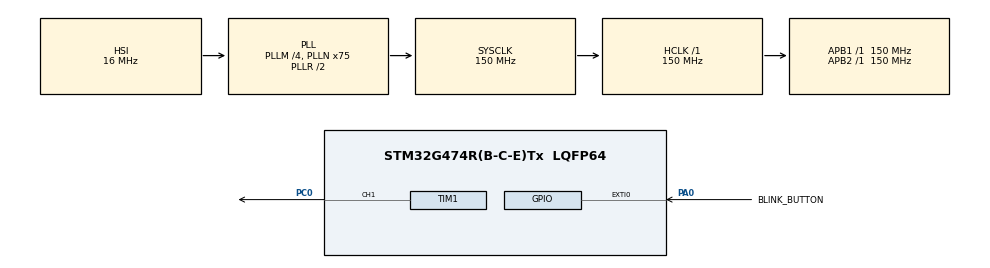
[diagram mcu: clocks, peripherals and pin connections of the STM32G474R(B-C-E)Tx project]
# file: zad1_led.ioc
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Dma.Request0=TIM1_CH1
Dma.TIM1_CH1.0.Direction=DMA_MEMORY_TO_PERIPH
Dma.TIM1_CH1.0.EventEnable=DISABLE
Dma.TIM1_CH1.0.Instance=DMA1_Channel1
Dma.TIM1_CH1.0.MemDataAlignment=DMA_MDATAALIGN_BYTE
Dma.TIM1_CH1.0.MemInc=DMA_MINC_ENABLE
Dma.TIM1_CH1.0.Mode=DMA_NORMAL
Dma.TIM1_CH1.0.PeriphDataAlignment=DMA_PDATAALIGN_HALFWORD
Dma.TIM1_CH1.0.PeriphInc=DMA_PINC_DISABLE
Dma.TIM1_CH1.0.Polarity=HAL_DMAMUX_REQ_GEN_RISING
Dma.TIM1_CH1.0.Priority=DMA_PRIORITY_LOW
Dma.TIM1_CH1.0.RequestNumber=1
Dma.TIM1_CH1.0.SignalID=NONE
Dma.TIM1_CH1.0.SyncEnable=DISABLE
Dma.TIM1_CH1.0.SyncPolarity=HAL_DMAMUX_SYNC_NO_EVENT
Dma.TIM1_CH1.0.SyncRequestNumber=1
Dma.TIM1_CH1.0.SyncSignalID=NONE
Mcu.Family=STM32G4
Mcu.Name=STM32G474R(B-C-E)Tx
Mcu.Package=LQFP64
NVIC.DMA1_Channel1_IRQn=true\:0\:0\:false\:false\:true\:false\:true\:true
NVIC.EXTI0_IRQn=true\:0\:0\:false\:false\:true\:true\:true\:true
NVIC.PriorityGroup=NVIC_PRIORITYGROUP_4
PA0.GPIO_Label=BLINK_BUTTON
PA0.GPIO_ModeDefaultEXTI=GPIO_MODE_IT_FALLING
PA0.Signal=GPXTI0
PC0.Signal=S_TIM1_CH1
ProjectManager.HeapSize=0x200
ProjectManager.StackSize=0x400
ProjectManager.TargetToolchain=STM32CubeIDE
RCC.ADC12Freq_Value=150000000
RCC.ADC345Freq_Value=150000000
RCC.AHBFreq_Value=150000000
RCC.APB1Freq_Value=150000000
RCC.APB1TimFreq_Value=150000000
RCC.APB2Freq_Value=150000000
RCC.APB2TimFreq_Value=150000000
RCC.CortexFreq_Value=150000000
RCC.EXTERNAL_CLOCK_VALUE=12288000
RCC.HCLKFreq_Value=150000000
RCC.HSE_VALUE=8000000
RCC.HSI48_VALUE=48000000
RCC.HSI_VALUE=16000000
RCC.LSE_VALUE=32768
RCC.PLLM=RCC_PLLM_DIV4
RCC.PLLN=75
RCC.SYSCLKFreq_VALUE=150000000
RCC.SYSCLKSource=RCC_SYSCLKSOURCE_PLLCLK
RCC.USBFreq_Value=150000000
RCC.VCOOutputFreq_Value=300000000
SH.S_TIM1_CH1.0=TIM1_CH1,PWM Generation1 CH1
TIM1.Channel-PWM\ Generation1\ CH1=TIM_CHANNEL_1
TIM1.PeriodNoDither=188
VP_TIM1_VS_ClockSourceINT.Mode=Internal
board=custom

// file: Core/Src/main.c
/* USER CODE BEGIN Header */
/**
  ******************************************************************************
  * @file           : main.c
  * @brief          : Main program body
  ******************************************************************************
  * @attention
  *
  * Copyright (c) 2024 STMicroelectronics.
  * All rights reserved.
  *
  * This software is licensed under terms that can be found in the LICENSE file
  * in the root directory of this software component.
  * If no LICENSE file comes with this software, it is provided AS-IS.
  *
  ******************************************************************************
  */
/* USER CODE END Header */
#include "main.h"
#include "dma.h"
#include "tim.h"
#include "gpio.h"

/* USER CODE BEGIN Includes */
#include <stdbool.h>
#include <ws2812b.h>
/* USER CODE END Includes */

/* USER CODE BEGIN PD */
//blue led blink parameters
#define NUM_BLUE_BLINKS 3
#define BLUE_LED_BLINK_PERIOD 1000

// red, green parameters
#define BLINK_PERIOD 3000 // in miliseconds
#define RESOLUTION 100 // brightness levels in one period for sawtooth wave

/* USER CODE END PD */

void SystemClock_Config(void);

/* USER CODE BEGIN 0 */

bool blink_button_flag = 0;

void HAL_GPIO_EXTI_Callback(uint16_t GPIO_Pin)
{
  if (GPIO_Pin == BLINK_BUTTON_Pin) {
	  blink_button_flag = 1;
  }
}
/* USER CODE END 0 */

int main(void)
{

  /* MCU Configuration--------------------------------------------------------*/

  /* Reset of all peripherals, Initializes the Flash interface and the Systick. */
  HAL_Init();

  /* Configure the system clock */
  SystemClock_Config();

  /* Initialize all configured peripherals */
  MX_GPIO_Init();
  MX_DMA_Init();
  MX_TIM1_Init();

  /* Infinite loop */
  /* USER CODE BEGIN WHILE */

  ws2812b_init();

  // red, green variables
  unsigned long prev_time = 0;
  int blink_counter = 0;
  int red_val = 0;
  int green_val = 0;

  //blue led variables
  int blue_val = 0;
  int blue_led_prev_blink = 0;
  int num_blinks_left = 0;

  while (1)
  {
	  //start blinking after button press
	  if(blink_button_flag){
		  num_blinks_left = NUM_BLUE_BLINKS * 2 - 1;  // *2 because state change are counted
		  blue_val = 100;
		  blue_led_prev_blink = HAL_GetTick();
		  blink_button_flag = 0;
	  }

	  // blue led blink
	  if(num_blinks_left && (HAL_GetTick() - blue_led_prev_blink) > BLUE_LED_BLINK_PERIOD/2){
		  //toogle blue led state
		  if(blue_val) blue_val = 0;
		  else blue_val = 100;
		  num_blinks_left --;
		  blue_led_prev_blink = HAL_GetTick();
	  }

	  // control red, green led
	  if((HAL_GetTick() - prev_time) > BLINK_PERIOD / RESOLUTION){
		  if(blink_counter < BLINK_PERIOD){
			  if(blink_counter < BLINK_PERIOD/2) red_val = 100;
			  else red_val = 0;
			  green_val = ((blink_counter * 100)/(BLINK_PERIOD - 1));
			  blink_counter += BLINK_PERIOD / RESOLUTION;
		  }
		  else{
			  blink_counter = 0;
		  }

		  prev_time = HAL_GetTick();
	  }

	  //send data to led
	  ws2812b_set_color(0, red_val, green_val, blue_val);
	  ws2812b_update();

    /* USER CODE END WHILE */

  }
}

void SystemClock_Config(void)
{
  RCC_OscInitTypeDef RCC_OscInitStruct = {0};
  RCC_ClkInitTypeDef RCC_ClkInitStruct = {0};

  /** Configure the main internal regulator output voltage
  */
  HAL_PWREx_ControlVoltageScaling(PWR_REGULATOR_VOLTAGE_SCALE1);

  /** Initializes the RCC Oscillators according to the specified parameters
  * in the RCC_OscInitTypeDef structure.
  */
  RCC_OscInitStruct.OscillatorType = RCC_OSCILLATORTYPE_HSI;
  RCC_OscInitStruct.HSIState = RCC_HSI_ON;
  RCC_OscInitStruct.HSICalibrationValue = RCC_HSICALIBRATION_DEFAULT;
  RCC_OscInitStruct.PLL.PLLState = RCC_PLL_ON;
  RCC_OscInitStruct.PLL.PLLSource = RCC_PLLSOURCE_HSI;
  RCC_OscInitStruct.PLL.PLLM = RCC_PLLM_DIV4;
  RCC_OscInitStruct.PLL.PLLN = 75;
  RCC_OscInitStruct.PLL.PLLP = RCC_PLLP_DIV2;
  RCC_OscInitStruct.PLL.PLLQ = RCC_PLLQ_DIV2;
  RCC_OscInitStruct.PLL.PLLR = RCC_PLLR_DIV2;
  if (HAL_RCC_OscConfig(&RCC_OscInitStruct) != HAL_OK)
  {
    Error_Handler();
  }

  /** Initializes the CPU, AHB and APB buses clocks
  */
  RCC_ClkInitStruct.ClockType = RCC_CLOCKTYPE_HCLK|RCC_CLOCKTYPE_SYSCLK
                              |RCC_CLOCKTYPE_PCLK1|RCC_CLOCKTYPE_PCLK2;
  RCC_ClkInitStruct.SYSCLKSource = RCC_SYSCLKSOURCE_PLLCLK;
  RCC_ClkInitStruct.AHBCLKDivider = RCC_SYSCLK_DIV1;
  RCC_ClkInitStruct.APB1CLKDivider = RCC_HCLK_DIV1;
  RCC_ClkInitStruct.APB2CLKDivider = RCC_HCLK_DIV1;

  if (HAL_RCC_ClockConfig(&RCC_ClkInitStruct, FLASH_LATENCY_4) != HAL_OK)
  {
    Error_Handler();
  }
}

void Error_Handler(void)
{
  __disable_irq();
  while (1)
  {
  }
}
